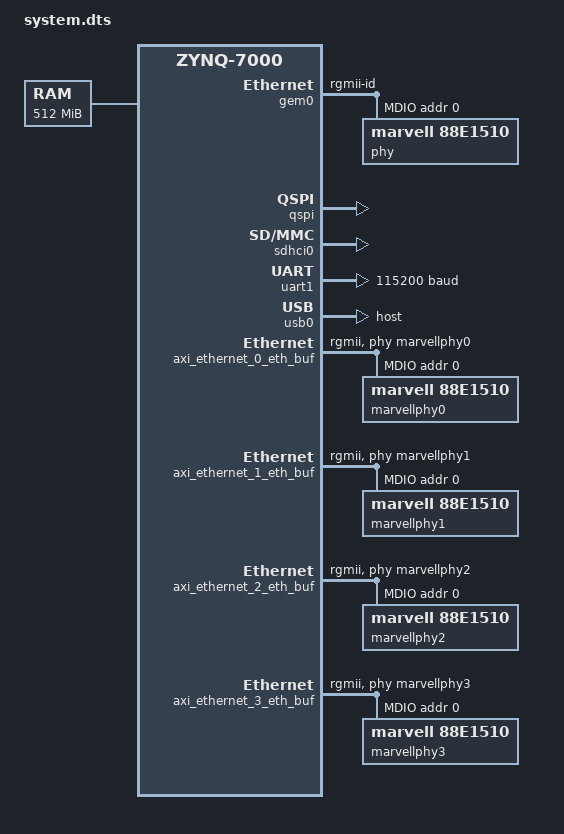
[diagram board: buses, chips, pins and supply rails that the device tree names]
/*
 * CAUTION: This file is automatically generated by Xilinx.
 * Version:  
 * Today is: Tue Apr 21 10:52:31 2015
*/


/dts-v1/;
/include/ "zynq-7000.dtsi"
/include/ "pl.dtsi"
/ {
	cpus {
		cpu@0 {
			operating-points = <666666 1000000 333333 1000000>;
		};
	};
	chosen {
		bootargs = "console=ttyPS0,115200 loglevel=7 root=/dev/nfs rw nfsroot=192.168.2.15:/home/tftpd,rsize=32768,wsize=32768,timeo=64,tcp ip=:::::eth0:dhcp rootwait earlyprintk rootfstype=ext4 devtmpfs.mount=1";
	};
	aliases {
		ethernet0 = &axi_ethernet_0_eth_buf;
		ethernet1 = &axi_ethernet_1_eth_buf;
		ethernet2 = &axi_ethernet_2_eth_buf;
		ethernet3 = &axi_ethernet_3_eth_buf;
		ethernet4 = &gem0;
		serial0 = &uart1;
	};
	memory {
		device_type = "memory";
		reg = <0x0 0x20000000>;
	};
};
&gem0 {
	local-mac-address = [00 0a 35 00 00 04];
	phy-mode = "rgmii-id";
	status = "okay";
	xlnx,ptp-enet-clock = <0x69f6bcb>;
        phy-handle = <2>;
	ps7_ethernet_0_mdio: mdio {
		#address-cells = <1>;
		#size-cells = <0>;
                phy@0 {
                   compatible = "marvell,88e1510";
                   device_type = "ethernet-phy";
                   reg = <0>;
			marvell,reg-init = <0x3 0x10 0xff00 0x1e 0x3 0x11 0xfff0 0xa>;
			linux,phandle = <0x2>;
			phandle = <0x2>;
                };
	};
};
&gpio0 {
	emio-gpio-width = <64>;
	gpio-mask-high = <0x0>;
	gpio-mask-low = <0x5600>;
};
&intc {
	num_cpus = <2>;
	num_interrupts = <96>;
};
&qspi {
	is-dual = <0>;
	num-cs = <1>;
	status = "okay";
};
&sdhci0 {
	clock-frequency = <50000000>;
	status = "okay";
};
&uart1 {
	current-speed = <115200>;
	device_type = "serial";
	port-number = <0>;
	status = "okay";
};
&usb0 {
	dr_mode = "host";
	phy_type = "ulpi";
	status = "okay";
};
&axi_ethernet_0_eth_buf {
	local-mac-address = [00 0a 35 00 00 00];
 	phy-handle = <&marvellphy0>;
 	phy-mode = "rgmii";
	axi_ethernet_0_eth_buf_mdio: mdio {
        #address-cells = <1>;
        #size-cells = <0>;
        marvellphy0: phy@0 {
            #address-cells = <1>;
            #size-cells = <0>;
            compatible = "marvell,88e1510";
            reg = <0>;
        };
    };
};
&axi_ethernet_1_eth_buf {
	local-mac-address = [00 0a 35 00 00 01];
    phy-handle = <&marvellphy1>;
    phy-mode = "rgmii";
    axi_ethernet_1_eth_buf_mdio: mdio {
        #address-cells = <1>;
        #size-cells = <0>;
        marvellphy1: phy@0 {
            #address-cells = <1>;
            #size-cells = <0>;
            compatible = "marvell,88e1510";
            reg = <0>;
        };
    };
};
&axi_ethernet_2_eth_buf {
	local-mac-address = [00 0a 35 00 00 02];
    phy-handle = <&marvellphy2>;
    phy-mode = "rgmii";
    axi_ethernet_2_eth_buf_mdio: mdio {
        #address-cells = <1>;
        #size-cells = <0>;
        marvellphy2: phy@0 {
            #address-cells = <1>;
            #size-cells = <0>;
            compatible = "marvell,88e1510";
            reg = <0>;
        };
    };
};
&axi_ethernet_3_eth_buf {
	local-mac-address = [00 0a 35 00 00 03];
    phy-handle = <&marvellphy3>;
    phy-mode = "rgmii";
    axi_ethernet_3_eth_buf_mdio: mdio {
        #address-cells = <1>;
        #size-cells = <0>;
        marvellphy3: phy@0 {
            #address-cells = <1>;
            #size-cells = <0>;
            compatible = "marvell,88e1510";
            reg = <0>;
        };
    };
};
&clkc {
	fclk-enable = <0x3>;
	ps-clk-frequency = <33333333>;
};
